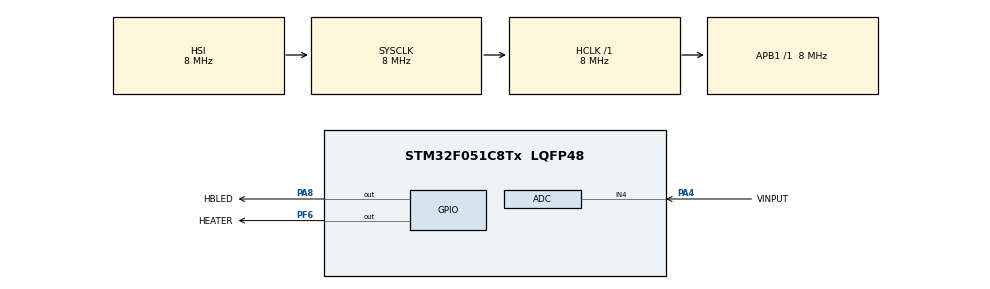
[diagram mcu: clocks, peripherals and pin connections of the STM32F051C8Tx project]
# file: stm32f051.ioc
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Mcu.Family=STM32F0
Mcu.Name=STM32F051C8Tx
Mcu.Package=LQFP48
PA4.GPIO_Label=VINPUT
PA4.Mode=IN4
PA4.Signal=ADC_IN4
PA8.GPIO_Label=HBLED
PA8.Signal=GPIO_Output
PF6.GPIO_Label=HEATER
PF6.Signal=GPIO_Output
ProjectManager.HeapSize=0x200
ProjectManager.StackSize=0x400
ProjectManager.TargetToolchain=STM32CubeIDE
RCC.AHBFreq_Value=8000000
RCC.APB1Freq_Value=8000000
RCC.APB1TimFreq_Value=8000000
RCC.HCLKFreq_Value=8000000
RCC.PLLMUL=RCC_PLL_MUL4
RCC.SYSCLKFreq_VALUE=8000000
board=custom

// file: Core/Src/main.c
/* USER CODE BEGIN Header */
/**
  ******************************************************************************
  * @file           : main.c
  * @brief          : Main program body
  ******************************************************************************
  * @attention
  *
  * Copyright (c) 2023 STMicroelectronics.
  * All rights reserved.
  *
  * This software is licensed under terms that can be found in the LICENSE file
  * in the root directory of this software component.
  * If no LICENSE file comes with this software, it is provided AS-IS.
  *
  ******************************************************************************
  */
/* USER CODE END Header */
#include "main.h"

ADC_HandleTypeDef hadc;

/* USER CODE BEGIN PV */
uint16_t	adcval;
uint8_t		percents;
uint8_t		bcnt = 0;
uint8_t		honcnt = 0;	// * 0.1s sildytuvas ijungtas (sek.)
uint8_t		hoffcnt = 0; // * 0.1s sildytuvas isjungtas (sek.)
uint8_t		ledstate = 0;
/* USER CODE END PV */

void SystemClock_Config(void);
static void MX_GPIO_Init(void);
static void MX_ADC_Init(void);

/* USER CODE BEGIN 0 */
//------------------------------------------------------------------------------
void	process_tick ()
{
		if	(adcval < 5)	{ // ADC triuksmas ties 0, sildymo nejungiame
			HAL_GPIO_WritePin(HEATER_GPIO_Port, HEATER_Pin, 0);
			return;
		}
		if	(!honcnt && !hoffcnt)
			hoffcnt = 100 - (honcnt = percents);
		if	(honcnt)	{	// ijungtos busenos ciklas
			HAL_GPIO_WritePin(HEATER_GPIO_Port, HEATER_Pin, 1);
			honcnt--;
			return;
		}
		if	(hoffcnt){	// isjungtos busenos ciklas
			HAL_GPIO_WritePin(HEATER_GPIO_Port, HEATER_Pin, 0);
			hoffcnt--;
		}
}
//------------------------------------------------------------------------------
void	blink () {
		if	(bcnt++ < 10)
			return;
		bcnt = 0;
		ledstate ^= 1;
		HAL_GPIO_WritePin(HBLED_GPIO_Port, HBLED_Pin, ledstate);
}
//------------------------------------------------------------------------------
/* USER CODE END 0 */

int main(void)
{

  /* MCU Configuration--------------------------------------------------------*/

  /* Reset of all peripherals, Initializes the Flash interface and the Systick. */
  HAL_Init();

  /* Configure the system clock */
  SystemClock_Config();

  /* Initialize all configured peripherals */
  MX_GPIO_Init();
  MX_ADC_Init();

  /* Infinite loop */
  while (1)
  {
      HAL_Delay(100);	//	0.1s = 10s / 100%
      HAL_ADC_Start(&hadc);
      HAL_ADC_PollForConversion(&hadc, 100);
      adcval = HAL_ADC_GetValue(&hadc);
      percents = (uint8_t) ((uint32_t)adcval * (uint32_t)100 / (uint32_t)4095);	// 12bit
      blink ();
      process_tick ();
  }
}

void SystemClock_Config(void)
{
  RCC_OscInitTypeDef RCC_OscInitStruct = {0};
  RCC_ClkInitTypeDef RCC_ClkInitStruct = {0};

  /** Initializes the RCC Oscillators according to the specified parameters
  * in the RCC_OscInitTypeDef structure.
  */
  RCC_OscInitStruct.OscillatorType = RCC_OSCILLATORTYPE_HSI|RCC_OSCILLATORTYPE_HSI14;
  RCC_OscInitStruct.HSIState = RCC_HSI_ON;
  RCC_OscInitStruct.HSI14State = RCC_HSI14_ON;
  RCC_OscInitStruct.HSICalibrationValue = RCC_HSICALIBRATION_DEFAULT;
  RCC_OscInitStruct.HSI14CalibrationValue = 16;
  RCC_OscInitStruct.PLL.PLLState = RCC_PLL_NONE;
  if (HAL_RCC_OscConfig(&RCC_OscInitStruct) != HAL_OK)
  {
    Error_Handler();
  }

  /** Initializes the CPU, AHB and APB buses clocks
  */
  RCC_ClkInitStruct.ClockType = RCC_CLOCKTYPE_HCLK|RCC_CLOCKTYPE_SYSCLK
                              |RCC_CLOCKTYPE_PCLK1;
  RCC_ClkInitStruct.SYSCLKSource = RCC_SYSCLKSOURCE_HSI;
  RCC_ClkInitStruct.AHBCLKDivider = RCC_SYSCLK_DIV1;
  RCC_ClkInitStruct.APB1CLKDivider = RCC_HCLK_DIV1;

  if (HAL_RCC_ClockConfig(&RCC_ClkInitStruct, FLASH_LATENCY_0) != HAL_OK)
  {
    Error_Handler();
  }
}

static void MX_ADC_Init(void)
{

  ADC_ChannelConfTypeDef sConfig = {0};

  /** Configure the global features of the ADC (Clock, Resolution, Data Alignment and number of conversion)
  */
  hadc.Instance = ADC1;
  hadc.Init.ClockPrescaler = ADC_CLOCK_ASYNC_DIV1;
  hadc.Init.Resolution = ADC_RESOLUTION_12B;
  hadc.Init.DataAlign = ADC_DATAALIGN_RIGHT;
  hadc.Init.ScanConvMode = ADC_SCAN_DIRECTION_FORWARD;
  hadc.Init.EOCSelection = ADC_EOC_SINGLE_CONV;
  hadc.Init.LowPowerAutoWait = DISABLE;
  hadc.Init.LowPowerAutoPowerOff = DISABLE;
  hadc.Init.ContinuousConvMode = DISABLE;
  hadc.Init.DiscontinuousConvMode = DISABLE;
  hadc.Init.ExternalTrigConv = ADC_SOFTWARE_START;
  hadc.Init.ExternalTrigConvEdge = ADC_EXTERNALTRIGCONVEDGE_NONE;
  hadc.Init.DMAContinuousRequests = DISABLE;
  hadc.Init.Overrun = ADC_OVR_DATA_PRESERVED;
  if (HAL_ADC_Init(&hadc) != HAL_OK)
  {
    Error_Handler();
  }

  /** Configure for the selected ADC regular channel to be converted.
  */
  sConfig.Channel = ADC_CHANNEL_4;
  sConfig.Rank = ADC_RANK_CHANNEL_NUMBER;
  sConfig.SamplingTime = ADC_SAMPLETIME_1CYCLE_5;
  if (HAL_ADC_ConfigChannel(&hadc, &sConfig) != HAL_OK)
  {
    Error_Handler();
  }

}

static void MX_GPIO_Init(void)
{
  GPIO_InitTypeDef GPIO_InitStruct = {0};

  /* GPIO Ports Clock Enable */
  __HAL_RCC_GPIOA_CLK_ENABLE();
  __HAL_RCC_GPIOF_CLK_ENABLE();

  /*Configure GPIO pin Output Level */
  HAL_GPIO_WritePin(HBLED_GPIO_Port, HBLED_Pin, GPIO_PIN_RESET);

  /*Configure GPIO pin Output Level */
  HAL_GPIO_WritePin(HEATER_GPIO_Port, HEATER_Pin, GPIO_PIN_RESET);

  /*Configure GPIO pin : HBLED_Pin */
  GPIO_InitStruct.Pin = HBLED_Pin;
  GPIO_InitStruct.Mode = GPIO_MODE_OUTPUT_PP;
  GPIO_InitStruct.Pull = GPIO_NOPULL;
  GPIO_InitStruct.Speed = GPIO_SPEED_FREQ_LOW;
  HAL_GPIO_Init(HBLED_GPIO_Port, &GPIO_InitStruct);

  /*Configure GPIO pin : HEATER_Pin */
  GPIO_InitStruct.Pin = HEATER_Pin;
  GPIO_InitStruct.Mode = GPIO_MODE_OUTPUT_PP;
  GPIO_InitStruct.Pull = GPIO_NOPULL;
  GPIO_InitStruct.Speed = GPIO_SPEED_FREQ_LOW;
  HAL_GPIO_Init(HEATER_GPIO_Port, &GPIO_InitStruct);

}

void Error_Handler(void)
{
  __disable_irq();
  while (1)
  {
  }
}
